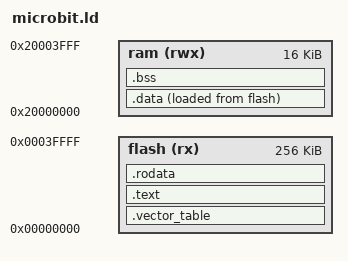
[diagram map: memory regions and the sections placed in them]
/*
 * =============================================================================
 * ARM Cortex-M0 (microbit / nRF51822) 链接脚本
 * =============================================================================
 *
 * 内存布局:
 *   Flash: 0x00000000 - 0x0003FFFF (256KB)  代码和只读数据
 *   RAM:   0x20000000 - 0x20003FFF (16KB)   读写数据、BSS、栈
 *
 * 段说明:
 *   .vector_table: 中断向量表，必须位于 Flash 起始位置 (地址 0x00000000)
 *   .text:         代码段
 *   .rodata:       只读数据 (字符串常量等)
 *   .data:         已初始化的全局/静态变量 (初始值在 Flash, 运行时复制到 RAM)
 *   .bss:          未初始化的全局/静态变量 (启动时清零)
 *   .stack:        栈空间 (放在 RAM 末尾，向下增长)
 * =============================================================================
 */

MEMORY
{
    flash (rx)  : ORIGIN = 0x00000000, LENGTH = 256K
    ram   (rwx) : ORIGIN = 0x20000000, LENGTH = 16K
}

/* 栈顶: RAM 结束地址 */
__stack_top = ORIGIN(ram) + LENGTH(ram);

/* 入口点 */
ENTRY(reset_handler)

SECTIONS
{
    /* -------------------------------------------------------------------------
     * 中断向量表 - Cortex-M0 要求向量表位于地址 0x00000000
     * 每个向量占 4 字节 (32 位地址)
     * [0] = 初始栈指针 (SP)
     * [1] = 复位向量 (PC)
     * [2..15] = 系统异常处理函数
     * [16..] = 外设中断处理函数
     * ------------------------------------------------------------------------- */
    .vector_table :
    {
        KEEP(*(.vector_table))
        . = ALIGN(4);
    } > flash

    /* -------------------------------------------------------------------------
     * .text 段: 程序代码
     * ------------------------------------------------------------------------- */
    .text :
    {
        *(.text .text.*)           /* 所有函数代码 */
        *(.glue_7)                 /* ARM -> Thumb 转换桩 (一般不用) */
        *(.glue_7t)                /* Thumb -> ARM 转换桩 (一般不用) */
        . = ALIGN(4);
    } > flash

    /* -------------------------------------------------------------------------
     * .rodata 段: 只读数据
     * 包括: const 变量、字符串字面量、switch 跳转表
     * ------------------------------------------------------------------------- */
    .rodata :
    {
        *(.rodata .rodata.*)
        . = ALIGN(4);
    } > flash

    /* -------------------------------------------------------------------------
     * .data 段: 已初始化的可读写数据
     * VMA (运行地址): RAM
     * LMA (加载地址): Flash (.rodata 之后)
     * 启动代码负责将数据从 Flash 复制到 RAM
     * ------------------------------------------------------------------------- */
    .data :
    {
        __data_start = .;
        *(.data .data.*)
        . = ALIGN(4);
        __data_end = .;
    } > ram AT > flash

    /* __data_load_start: .data 在 Flash 中的加载地址 */
    __data_load_start = LOADADDR(.data);

    /* -------------------------------------------------------------------------
     * .bss 段: 未初始化的静态变量 (C 标准保证初始化为 0)
     * 启动代码负责清零此区域
     * ------------------------------------------------------------------------- */
    .bss :
    {
        __bss_start = .;
        *(.bss .bss.*)
        *(COMMON)
        . = ALIGN(4);
        __bss_end = .;
    } > ram

    /* -------------------------------------------------------------------------
     * 堆和栈边界符号 (供 syscalls.c 中的 _sbrk 使用)
     * 栈从 __stack_top 向下增长
     * 堆从 __heap_start 开始向上增长 (如果使用 malloc)
     * ------------------------------------------------------------------------- */
    __heap_start = .;
    /* __stack_top 已在文件开头定义 (RAM 末尾) */
}
